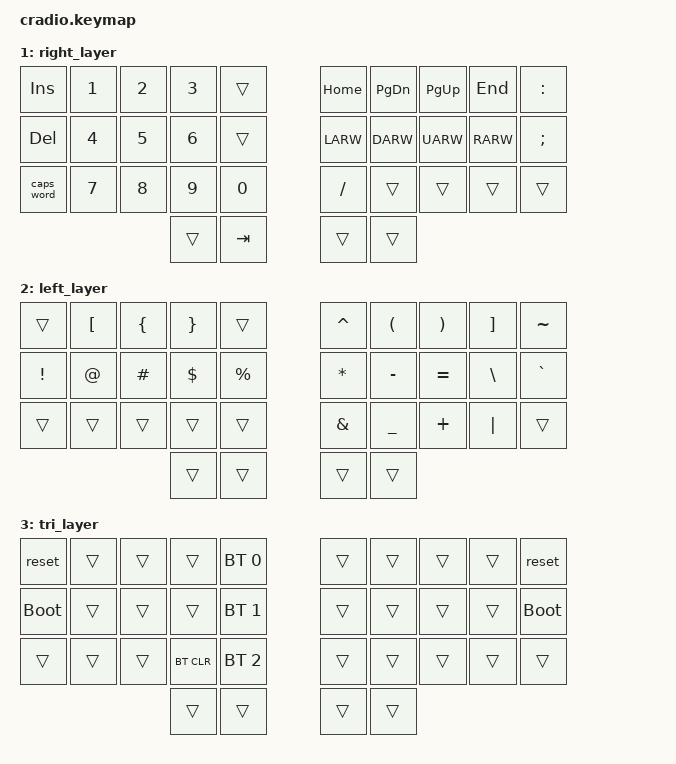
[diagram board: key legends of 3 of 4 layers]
// Copyright (c) 2022 The ZMK Contributors
// SPDX-License-Identifier: MIT

/*  The Mechboards UK board has some pin layout changes.
    Since they only provide a QMK firmware, we try to
    map the changes from the QMK firmware to ZMK.

    This is the default QMK layout:
    (https://github.com/qmk/qmk_firmware/blob/10631b4b480c618c72b4c6b908025f2408e15f5b/keyboards/ferris/sweep/config.h)

    #define DIRECT_PINS { \
        { E6, F7, F6, F5, F4 }, \
        { B1, B3, B2, B6, D3 }, \
        { D1, D0, D4, C6, D7 }, \
        { B4, B5, NO_PIN, NO_PIN, NO_PIN } \
    }

    #define DIRECT_PINS_RIGHT { \
        { F4, F5, F6, F7, E6 }, \
        { D3, B6, B2, B3, B1 }, \
        { D7, C6, D4, D0, D1 }, \
        { B5, B4, NO_PIN, NO_PIN, NO_PIN } \
    }

    This is the Mechboards layout:
    (https://github.com/qmk/qmk_firmware/blob/10631b4b480c618c72b4c6b908025f2408e15f5b/keyboards/ferris/sweep_choc_mbuk/config.h)

    #define DIRECT_PINS { \
        { D7, F7, F6, F5, F4 }, \
        { B1, B3, B2, B6, D3 }, \
        { D1, D0, D4, C6, E6 }, \
        { B5, B4, NO_PIN, NO_PIN, NO_PIN } \
    }

    #define DIRECT_PINS_RIGHT { \
        { F4, F5, F6, F7, D7 }, \
        { D1, D3, B2, B3, B1 }, \
        { B4, E6, C6, B5, D0 }, \
        { D4, B6, NO_PIN, NO_PIN, NO_PIN } \
    }

*/

&kscan0 {
	input-gpios
	= <&pro_micro  6 (GPIO_ACTIVE_LOW | GPIO_PULL_UP)>
	, <&pro_micro 18 (GPIO_ACTIVE_LOW | GPIO_PULL_UP)>
	, <&pro_micro 19 (GPIO_ACTIVE_LOW | GPIO_PULL_UP)>
	, <&pro_micro 20 (GPIO_ACTIVE_LOW | GPIO_PULL_UP)>
	, <&pro_micro 21 (GPIO_ACTIVE_LOW | GPIO_PULL_UP)>
	, <&pro_micro 15 (GPIO_ACTIVE_LOW | GPIO_PULL_UP)>
	, <&pro_micro 14 (GPIO_ACTIVE_LOW | GPIO_PULL_UP)>
	, <&pro_micro 16 (GPIO_ACTIVE_LOW | GPIO_PULL_UP)>
	, <&pro_micro 10 (GPIO_ACTIVE_LOW | GPIO_PULL_UP)>
	, <&pro_micro  1 (GPIO_ACTIVE_LOW | GPIO_PULL_UP)>
	, <&pro_micro  2 (GPIO_ACTIVE_LOW | GPIO_PULL_UP)>
	, <&pro_micro  3 (GPIO_ACTIVE_LOW | GPIO_PULL_UP)>
	, <&pro_micro  4 (GPIO_ACTIVE_LOW | GPIO_PULL_UP)>
	, <&pro_micro  5 (GPIO_ACTIVE_LOW | GPIO_PULL_UP)>
	, <&pro_micro  7 (GPIO_ACTIVE_LOW | GPIO_PULL_UP)>
	, <&pro_micro  9 (GPIO_ACTIVE_LOW | GPIO_PULL_UP)>
	, <&pro_micro  8 (GPIO_ACTIVE_LOW | GPIO_PULL_UP)>
	;
};

/*  For reference: This is the default layout in ZMK:
    &kscan0 {
        input-gpios
        = <&pro_micro  7 (GPIO_ACTIVE_LOW | GPIO_PULL_UP)>
        , <&pro_micro 18 (GPIO_ACTIVE_LOW | GPIO_PULL_UP)>
        , <&pro_micro 19 (GPIO_ACTIVE_LOW | GPIO_PULL_UP)>
        , <&pro_micro 20 (GPIO_ACTIVE_LOW | GPIO_PULL_UP)>
        , <&pro_micro 21 (GPIO_ACTIVE_LOW | GPIO_PULL_UP)>
        , <&pro_micro 15 (GPIO_ACTIVE_LOW | GPIO_PULL_UP)>
        , <&pro_micro 14 (GPIO_ACTIVE_LOW | GPIO_PULL_UP)>
        , <&pro_micro 16 (GPIO_ACTIVE_LOW | GPIO_PULL_UP)>
        , <&pro_micro 10 (GPIO_ACTIVE_LOW | GPIO_PULL_UP)>
        , <&pro_micro  1 (GPIO_ACTIVE_LOW | GPIO_PULL_UP)>
        , <&pro_micro  2 (GPIO_ACTIVE_LOW | GPIO_PULL_UP)>
        , <&pro_micro  3 (GPIO_ACTIVE_LOW | GPIO_PULL_UP)>
        , <&pro_micro  4 (GPIO_ACTIVE_LOW | GPIO_PULL_UP)>
        , <&pro_micro  5 (GPIO_ACTIVE_LOW | GPIO_PULL_UP)>
        , <&pro_micro  6 (GPIO_ACTIVE_LOW | GPIO_PULL_UP)>
        , <&pro_micro  8 (GPIO_ACTIVE_LOW | GPIO_PULL_UP)>
        , <&pro_micro  9 (GPIO_ACTIVE_LOW | GPIO_PULL_UP)>
        ;
    };
*/

#include <behaviors.dtsi>
#include <dt-bindings/zmk/keys.h>
#include <dt-bindings/zmk/bt.h>

// Home row mods macro
#define HRML(k1,k2,k3,k4) &ht LSHFT k1  &ht LALT k2  &ht LCTRL k3  &ht LGUI k4
#define HRMR(k1,k2,k3,k4) &ht RGUI k1  &ht RCTRL k2  &ht RALT k3  &ht RSHFT k4

/ {
    behaviors {
        ht: hold_tap {
            label = "hold_tap";
            compatible = "zmk,behavior-hold-tap";
            #binding-cells = <2>;
            flavor = "tap-preferred";
            tapping-term-ms = <220>;
            quick-tap-ms = <150>;
            global-quick-tap;
            bindings = <&kp>, <&kp>;
        };
    };

    conditional_layers {
        compatible = "zmk,conditional-layers";
        tri_layer {
            if-layers = <1 2>;
            then-layer = <3>;
        };
    };

    keymap {
        compatible = "zmk,keymap";
        default_layer {
            bindings = <
        //╭──────────┬──────────┬──────────┬──────────┬──────────╮   ╭──────────┬──────────┬──────────┬──────────┬──────────╮
        //│ ' "      │ , <      │  . >     │  P       │  Y       │   │  F       │  G       │  C       │  R       │  L       │
            &kp SQT    &kp COMMA   &kp DOT    &kp P      &kp Y          &kp F      &kp G      &kp C      &kp R      &kp L
        //├──────────┼──────────┼──────────┼──────────┼──────────┤   ├──────────┼──────────┼──────────┼──────────┼──────────┤
        //│  A       │  O       │  E       │  U       │  I       │   │  D       │  H       │  T       │  N       │ S        │
            HRML(A,     O,         E,         U)         &kp I          &kp D      HRMR(H,    T,         N,        S)
        //├──────────┼──────────┼──────────┼──────────┼──────────┤   ├──────────┼──────────┼──────────┼──────────┼──────────┤
        //│          │  Q       │  J       │  K       │  X       │   │  B       │  M       │  W       │ V        │ Z        │
            &none       &kp Q      &kp J      &kp K      &kp X          &kp B      &kp M      &kp W     &kp V      &kp Z
        //╰──────────┴──────────┴──────────┼──────────┼──────────┤   ├──────────┼──────────┼──────────┴──────────┴──────────╯
                                            &lt 2 ESC   &kp SPACE     &kp ENTER  &lt 1 BSPC
        //                                 ╰──────────┴──────────╯   ╰──────────┴──────────╯
            >;
        };

        right_layer {
            bindings = <
        //╭──────────┬──────────┬──────────┬──────────┬──────────╮   ╭──────────┬──────────┬──────────┬──────────┬──────────╮
        //│ INSERT   │  1       │  2       │  3       │          │   │ HOME     │ PAGE DN  │ PAGE UP  │ END      │  :       │
            &kp INS    &kp N1     &kp N2     &kp N3     &trans         &kp HOME   &kp PG_DN  &kp PG_UP  &kp END    &kp COLON
        //├──────────┼──────────┼──────────┼──────────┼──────────┤   ├──────────┼──────────┼──────────┼──────────┼──────────┤
        //│ DELETE   │  4       │  5       │  6       │          │   │ LEFT     │ DOWN     │ UP       │ RIGHT    │  ;       │
            &kp DEL    &kp N4     &kp N5     &kp N6     &trans         &kp LARW   &kp DARW   &kp UARW   &kp RARW   &kp SEMI
        //├──────────┼──────────┼──────────┼──────────┼──────────┤   ├──────────┼──────────┼──────────┼──────────┼──────────┤
        //│ CAPS     │  7       │  8       │  9       │  0       │   │ / ?      │          │          │          │          │
           &caps_word  &kp N7     &kp N8     &kp N9     &kp N0         &kp FSLH     &trans     &trans     &trans     &trans
        //╰──────────┴──────────┴──────────┼──────────┼──────────┤   ├──────────┼──────────┼──────────┴──────────┴──────────╯
                                             &trans     &kp TAB        &trans     &trans
        //                                 ╰──────────┴──────────╯   ╰──────────┴──────────╯
            >;
        };

        left_layer {
            bindings = <
        //╭──────────┬──────────┬──────────┬──────────┬──────────╮   ╭──────────┬──────────┬──────────┬──────────┬──────────╮
        //│          │  [       │  {       │  }       │          │   │  ^       │  (       │  )       │  ]       │  ~       │
            &trans     &kp LBKT   &kp LBRC   &kp RBRC   &trans         &kp CARET  &kp LPAR   &kp RPAR   &kp RBKT   &kp TILDE
        //├──────────┼──────────┼──────────┼──────────┼──────────┤   ├──────────┼──────────┼──────────┼──────────┼──────────┤
        //│  !       │  @       │  #       │  $       │  %       │   │  *       │  -       │  =       │  \       │  `       │
            &kp EXCL   &kp AT     &kp HASH   &kp DLLR   &kp PRCNT      &kp ASTRK  &kp MINUS  &kp EQUAL  &kp BSLH   &kp GRAVE
        //├──────────┼──────────┼──────────┼──────────┼──────────┤   ├──────────┼──────────┼──────────┼──────────┼──────────┤
        //│          │          │          │          │          │   │  &       │  _       │  +       │  │       │          │
            &trans     &trans     &trans     &trans     &trans         &kp AMPS   &kp UNDER  &kp PLUS   &kp PIPE   &trans
        //╰──────────┴──────────┴──────────┼──────────┼──────────┤   ├──────────┼──────────┼──────────┴──────────┴──────────╯
                                             &trans     &trans         &trans     &trans
        //                                 ╰──────────┴──────────╯   ╰──────────┴──────────╯
            >;
        };

        tri_layer {
            bindings = <
        //╭──────────┬──────────┬──────────┬──────────┬──────────╮   ╭──────────┬──────────┬──────────┬──────────┬──────────╮
        //│ RESET    │          │          │          │PROFILE 0 │   │          │          │          │          │  RESET   │
            &reset     &trans     &trans     &trans    &bt BT_SEL 0    &trans     &trans     &trans     &trans      &reset
        //├──────────┼──────────┼──────────┼──────────┼──────────┤   ├──────────┼──────────┼──────────┼──────────┼──────────┤
        //│BOOTLOADER│          │          │          │PROFILE 1 │   │          │          │          │          │BOOTLOADER│
          &bootloader  &trans     &trans     &trans    &bt BT_SEL 1    &trans     &trans     &trans     &trans    &bootloader
        //├──────────┼──────────┼──────────┼──────────┼──────────┤   ├──────────┼──────────┼──────────┼──────────┼──────────┤
        //│          │          │          │ CLEAR BT │PROFILE 2 │   │          │          │          │          │          │
            &trans     &trans     &trans    &bt BT_CLR &bt BT_SEL 2    &trans     &trans     &trans     &trans     &trans
        //╰──────────┴──────────┴──────────┼──────────┼──────────┤   ├──────────┼──────────┼──────────┴──────────┴──────────╯
                                             &trans     &trans         &trans     &trans
        //                                 ╰──────────┴──────────╯   ╰──────────┴──────────╯
            >;
        };
    };
};
